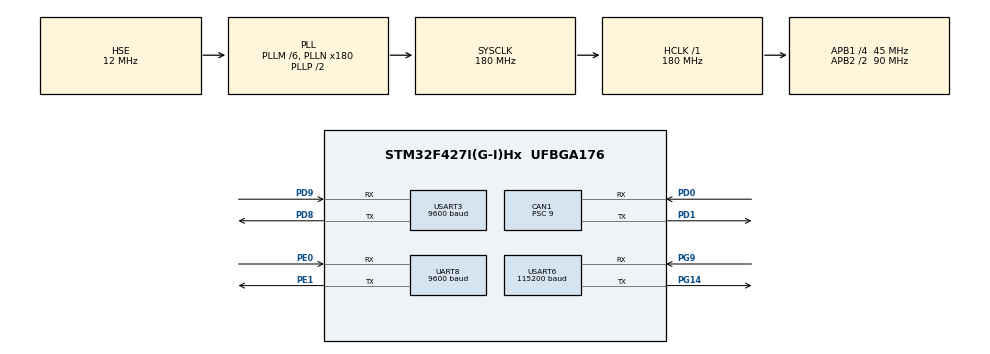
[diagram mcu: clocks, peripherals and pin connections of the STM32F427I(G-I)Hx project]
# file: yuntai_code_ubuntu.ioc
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Mcu.Family=STM32F4
Dma.USART3_RX.1.Mode=DMA_CIRCULAR
RCC.CortexFreq_Value=180000000
PD9.Mode=Asynchronous
RCC.SYSCLKSource=RCC_SYSCLKSOURCE_PLLCLK
ProjectManager.StackSize=0x400
Dma.UART8_RX.2.PeriphInc=DMA_PINC_DISABLE
Dma.USART6_RX.0.Instance=DMA2_Stream1
Dma.USART6_RX.0.FIFOMode=DMA_FIFOMODE_DISABLE
Dma.USART3_RX.1.MemInc=DMA_MINC_ENABLE
USART3.BaudRate=9600
Dma.USART3_RX.1.Instance=DMA1_Stream1
Dma.USART6_RX.0.Direction=DMA_PERIPH_TO_MEMORY
PH0/OSC_IN.Mode=HSE-External-Oscillator
RCC.HCLKFreq_Value=180000000
Dma.UART8_RX.2.MemDataAlignment=DMA_MDATAALIGN_BYTE
RCC.APB2TimFreq_Value=180000000
Dma.USART3_RX.1.PeriphDataAlignment=DMA_PDATAALIGN_BYTE
PH1/OSC_OUT.Signal=RCC_OSC_OUT
PD0.Signal=CAN1_RX
PD8.Signal=USART3_TX
PE1.Signal=UART8_TX
Dma.UART8_RX.2.Direction=DMA_PERIPH_TO_MEMORY
RCC.AHBFreq_Value=180000000
RCC.HSE_VALUE=12000000
PG14.Mode=Asynchronous
Dma.USART3_RX.1.Priority=DMA_PRIORITY_LOW
PA14.Mode=Serial_Wire
NVIC.TIM2_IRQn=true\:0\:0\:false\:false\:true\:true\:true
PH1/OSC_OUT.Mode=HSE-External-Oscillator
CAN1.Prescaler=9
Mcu.Package=UFBGA176
TIM2.Prescaler=7199
Dma.USART3_RX.1.FIFOMode=DMA_FIFOMODE_DISABLE
UART8.BaudRate=9600
USART6.VirtualMode=VM_ASYNC
Dma.USART3_RX.1.Direction=DMA_PERIPH_TO_MEMORY
Dma.UART8_RX.2.PeriphDataAlignment=DMA_PDATAALIGN_BYTE
Dma.USART6_RX.0.Mode=DMA_CIRCULAR
USART6.BaudRate=115200
Dma.USART6_RX.0.MemDataAlignment=DMA_MDATAALIGN_BYTE
RCC.APB2CLKDivider=RCC_HCLK_DIV2
Dma.Request2=UART8_RX
Dma.Request1=USART3_RX
RCC.APB1TimFreq_Value=90000000
Dma.UART8_RX.2.Mode=DMA_CIRCULAR
NVIC.DMA1_Stream6_IRQn=true\:0\:0\:false\:false\:true\:false\:true
Dma.Request0=USART6_RX
CAN1.CalculateTimeBit=1000.00
CAN1.CalculateTimeQuantum=200.0
RCC.PLLSourceVirtual=RCC_PLLSOURCE_HSE
Dma.UART8_RX.2.MemInc=DMA_MINC_ENABLE
Dma.USART6_RX.0.PeriphInc=DMA_PINC_DISABLE
PG9.Signal=USART6_RX
Dma.UART8_RX.2.Instance=DMA1_Stream6
PE1.Mode=Asynchronous
CAN1.CalculateBaudRate=1000000
PG9.Mode=Asynchronous
PD1.Signal=CAN1_TX
Dma.USART3_RX.1.MemDataAlignment=DMA_MDATAALIGN_BYTE
PD9.Signal=USART3_RX
NVIC.DMA1_Stream1_IRQn=true\:0\:0\:false\:false\:true\:false\:true
NVIC.DMA2_Stream1_IRQn=true\:0\:0\:false\:false\:true\:false\:true
RCC.APB1CLKDivider=RCC_HCLK_DIV4
UART8.VirtualMode=Asynchronous
Dma.UART8_RX.2.Priority=DMA_PRIORITY_LOW
PA13.Signal=SYS_JTMS-SWDIO
Dma.UART8_RX.2.FIFOMode=DMA_FIFOMODE_DISABLE
CAN1.BS1=CAN_BS1_3TQ
ProjectManager.TargetToolchain=STM32CubeIDE
RCC.LSE_VALUE=32768
PD8.Mode=Asynchronous
PG14.Signal=USART6_TX
board=custom
RCC.VCOOutputFreq_Value=360000000
PD1.Mode=CAN_Activate
PH0/OSC_IN.Signal=RCC_OSC_IN
RCC.APB2Freq_Value=90000000
VP_TIM2_VS_ClockSourceINT.Mode=Internal
TIM2.Period=1
PA13.Mode=Serial_Wire
Mcu.Name=STM32F427I(G-I)Hx
PE0.Signal=UART8_RX
PD0.Mode=CAN_Activate
RCC.48MHZClocksFreq_Value=90000000
RCC.SYSCLKFreq_VALUE=180000000
Dma.USART6_RX.0.PeriphDataAlignment=DMA_PDATAALIGN_BYTE
USART3.VirtualMode=VM_ASYNC
PA14.Signal=SYS_JTCK-SWCLK
ProjectManager.HeapSize=0x200
RCC.HSI_VALUE=16000000
Dma.USART6_RX.0.Priority=DMA_PRIORITY_LOW
NVIC.PriorityGroup=NVIC_PRIORITYGROUP_4
Dma.USART6_RX.0.MemInc=DMA_MINC_ENABLE
RCC.PLLM=6
RCC.PLLN=180
RCC.APB1Freq_Value=45000000
PE0.Mode=Asynchronous
NVIC.CAN1_RX0_IRQn=true\:0\:0\:false\:false\:true\:true\:true
Dma.USART3_RX.1.PeriphInc=DMA_PINC_DISABLE

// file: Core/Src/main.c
/* USER CODE BEGIN Header */
/**
  ******************************************************************************
  * @file           : main.c
  * @brief          : Main program body
  ******************************************************************************
  * @attention
  *
  * <h2><center>&copy; Copyright (c) 2021 STMicroelectronics.
  * All rights reserved.</center></h2>
  *
  * This software component is licensed by ST under BSD 3-Clause license,
  * the "License"; You may not use this file except in compliance with the
  * License. You may obtain a copy of the License at:
  *                        opensource.org/licenses/BSD-3-Clause
  *
  ******************************************************************************
  */
/* USER CODE END Header */
#include "main.h"
#include "can.h"
#include "dma.h"
#include "tim.h"
#include "usart.h"
#include "gpio.h"

void SystemClock_Config(void);

int main(void)
{

  /* MCU Configuration--------------------------------------------------------*/

  /* Reset of all peripherals, Initializes the Flash interface and the Systick. */
a36 t   HAL_Init();

  /* Configure the system clock */
  SystemClock_Config();

  /* Initialize all configured peripherals */
  MX_GPIO_Init();
  MX_DMA_Init();
  MX_CAN1_Init();
  MX_USART6_UART_Init();
  MX_USART3_UART_Init();
  MX_UART8_Init();
  MX_TIM2_Init();
  /* USER CODE BEGIN 2 */
  proj_init();
  /* USER CODE END 2 */

  /* Infinite loop */
  while (1)
  {

  }
}

void SystemClock_Config(void)
{
  RCC_OscInitTypeDef RCC_OscInitStruct = {0};
  RCC_ClkInitTypeDef RCC_ClkInitStruct = {0};

  /** Configure the main internal regulator output voltage
  */
  __HAL_RCC_PWR_CLK_ENABLE();
  __HAL_PWR_VOLTAGESCALING_CONFIG(PWR_REGULATOR_VOLTAGE_SCALE1);
  /** Initializes the RCC Oscillators according to the specified parameters
  * in the RCC_OscInitTypeDef structure.
  */
  RCC_OscInitStruct.OscillatorType = RCC_OSCILLATORTYPE_HSE;
  RCC_OscInitStruct.HSEState = RCC_HSE_ON;
  RCC_OscInitStruct.PLL.PLLState = RCC_PLL_ON;
  RCC_OscInitStruct.PLL.PLLSource = RCC_PLLSOURCE_HSE;
  RCC_OscInitStruct.PLL.PLLM = 6;
  RCC_OscInitStruct.PLL.PLLN = 180;
  RCC_OscInitStruct.PLL.PLLP = RCC_PLLP_DIV2;
  RCC_OscInitStruct.PLL.PLLQ = 4;
  if (HAL_RCC_OscConfig(&RCC_OscInitStruct) != HAL_OK)
  {
    Error_Handler();
  }
  /** Activate the Over-Drive mode
  */
  if (HAL_PWREx_EnableOverDrive() != HAL_OK)
  {
    Error_Handler();
  }
  /** Initializes the CPU, AHB and APB buses clocks
  */
  RCC_ClkInitStruct.ClockType = RCC_CLOCKTYPE_HCLK|RCC_CLOCKTYPE_SYSCLK
                              |RCC_CLOCKTYPE_PCLK1|RCC_CLOCKTYPE_PCLK2;
  RCC_ClkInitStruct.SYSCLKSource = RCC_SYSCLKSOURCE_PLLCLK;
  RCC_ClkInitStruct.AHBCLKDivider = RCC_SYSCLK_DIV1;
  RCC_ClkInitStruct.APB1CLKDivider = RCC_HCLK_DIV4;
  RCC_ClkInitStruct.APB2CLKDivider = RCC_HCLK_DIV2;

  if (HAL_RCC_ClockConfig(&RCC_ClkInitStruct, FLASH_LATENCY_5) != HAL_OK)
  {
    Error_Handler();
  }
}

void Error_Handler(void)
{
  __disable_irq();
  while (1)
  {
  }
}

/************************ (C) COPYRIGHT STMicroelectronics *****END OF FILE****/
